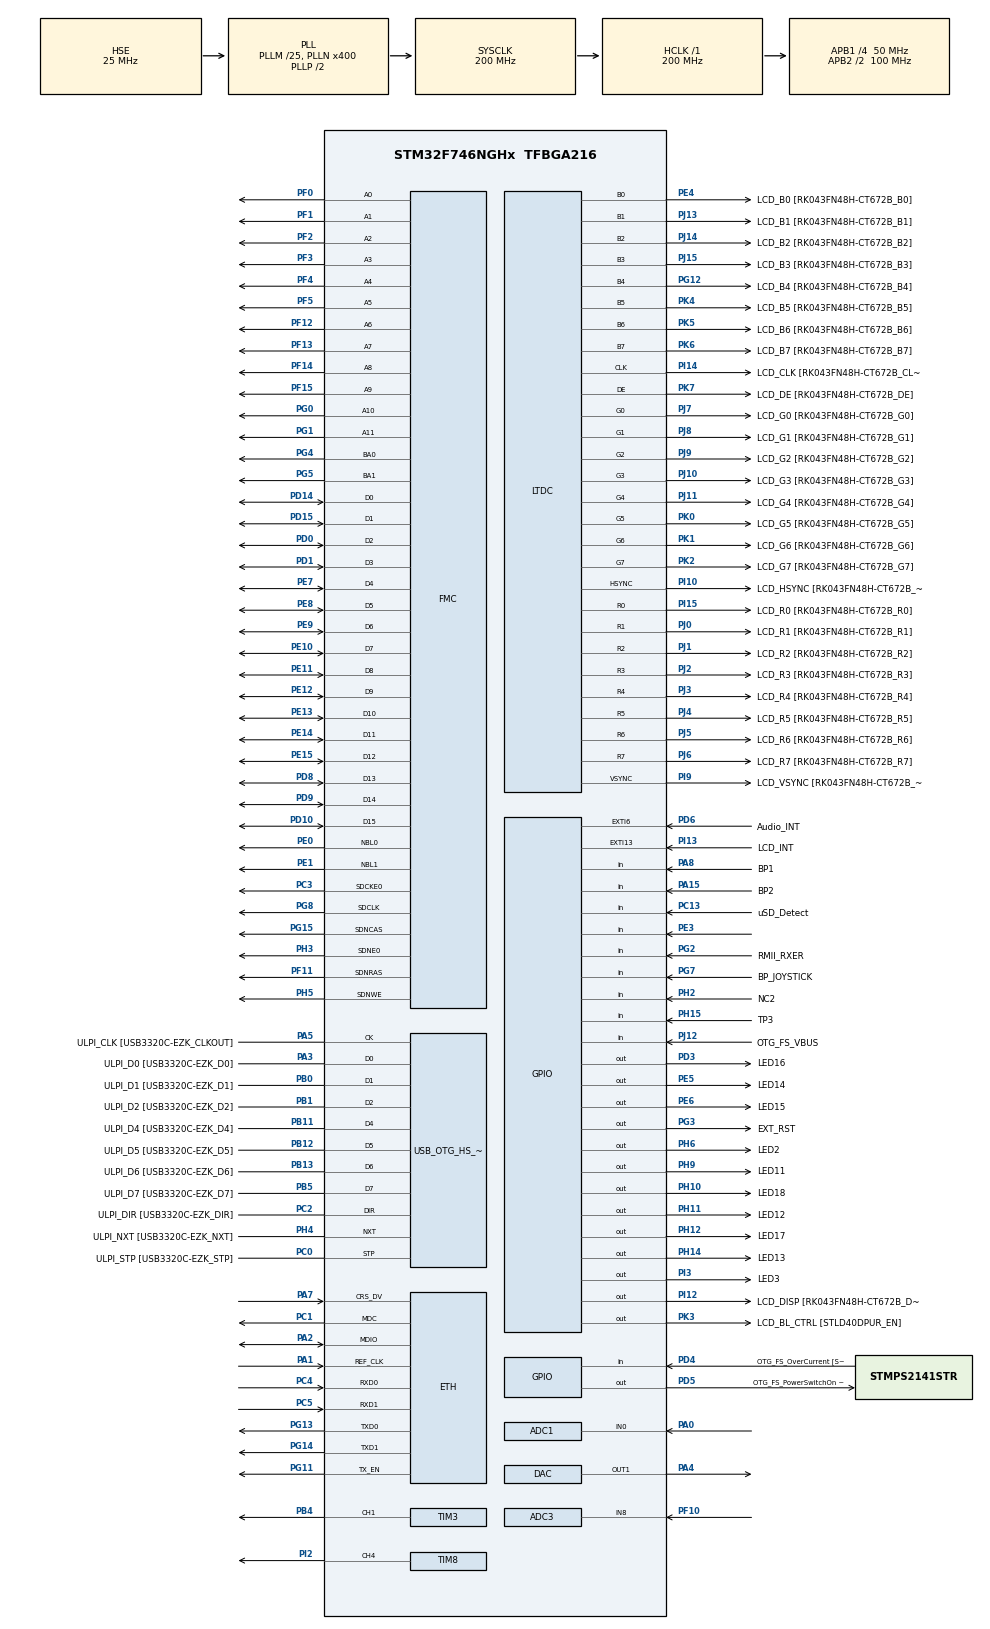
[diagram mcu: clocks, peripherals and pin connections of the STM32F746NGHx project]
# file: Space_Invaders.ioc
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ADC1.Channel-1\#ChannelRegularConversion=ADC_CHANNEL_0
ADC1.NbrOfConversionFlag=1
ADC1.Rank-1\#ChannelRegularConversion=1
ADC1.SamplingTime-1\#ChannelRegularConversion=ADC_SAMPLETIME_3CYCLES
ADC1.master=1
ADC3.Channel-0\#ChannelRegularConversion=ADC_CHANNEL_8
CORTEX_M7.PREFETCH_ENABLE=1
ETH.MACAddr=00\:80\:E1\:00\:E0\:00
ETH.MediaInterface=ETH_MEDIA_INTERFACE_RMII
FREERTOS.INCLUDE_vTaskDelayUntil=1
FREERTOS.Mutexes01=MutexLCD,Dynamic,NULL
FREERTOS.Queues01=Queue_F,8,enum End_type,0,Dynamic,NULL,NULL;Queue_N,8,struct Missile,0,Dynamic,NULL,NULL;Queue_J,8,uint8_t,0,Dynamic,NULL,NULL;Queue_E,8,struct Collision,0,Dynamic,NULL,NULL
FREERTOS.Tasks01=GameMaster,2,1024,f_GameMaster,Default,NULL,Dynamic,NULL,NULL;Joueur_1,1,1024,f_Joueur_1,Default,NULL,Dynamic,NULL,NULL;Block_Enemie,-2,1024,f_block_enemie,Default,NULL,Dynamic,NULL,NULL;Projectile,0,1024,f_projectile,Default,NULL,Dynamic,Dynamic,NULL;HUD,-1,1024,f_HUD,Default,NULL,Dynamic,NULL,NULL
FREERTOS.configCHECK_FOR_STACK_OVERFLOW=2
FREERTOS.configENABLE_FPU=1
FREERTOS.configGENERATE_RUN_TIME_STATS=0
FREERTOS.configRECORD_STACK_HIGH_ADDRESS=1
FREERTOS.configTOTAL_HEAP_SIZE=32768
FREERTOS.configUSE_APPLICATION_TASK_TAG=1
FREERTOS.configUSE_COUNTING_SEMAPHORES=1
FREERTOS.configUSE_IDLE_HOOK=1
FREERTOS.configUSE_MALLOC_FAILED_HOOK=1
FREERTOS.configUSE_RECURSIVE_MUTEXES=1
LTDC.ActiveH=272
LTDC.ActiveW=480
LTDC.Alpha_L0=255
LTDC.BlendingFactor1_L0=LTDC_BLENDING_FACTOR1_PAxCA
LTDC.BlendingFactor2_L0=LTDC_BLENDING_FACTOR2_PAxCA
LTDC.FBStartAdress_L0=0xC0000000
LTDC.HBP=13
LTDC.HFP=32
LTDC.HSync=41
LTDC.ImageHeight_L0=272
LTDC.ImageWidth_L0=480
LTDC.Layers=0
LTDC.PixelFormat_L0=LTDC_PIXEL_FORMAT_RGB565
LTDC.VSync=10
LTDC.WindowX1_L0=480
LTDC.WindowY1_L0=272
LWIP.Version=v2.1.2_Cube
Mcu.Family=STM32F7
Mcu.Name=STM32F746NGHx
Mcu.Package=TFBGA216
NVIC.ETH_IRQn=true\:5\:0\:false\:false\:true\:true\:false\:true
NVIC.LTDC_IRQn=true\:5\:0\:false\:false\:true\:true\:true\:true
NVIC.PriorityGroup=NVIC_PRIORITYGROUP_4
NVIC.TIM6_DAC_IRQn=true\:0\:0\:false\:false\:true\:false\:false\:true
NVIC.TimeBase=TIM6_DAC_IRQn
NVIC.TimeBaseIP=TIM6
PA0/WKUP.Signal=ADCx_IN0
PA1.Mode=RMII
PA1.Signal=ETH_REF_CLK
PA13.GPIO_Label=SWDIO
PA13.Mode=Serial_Wire
PA13.Signal=SYS_JTMS-SWDIO
PA14.GPIO_Label=SWCLK
PA14.Mode=Serial_Wire
PA14.Signal=SYS_JTCK-SWCLK
PA15.GPIO_Label=BP2
PA15.Signal=GPIO_Input
PA2.Mode=RMII
PA2.Signal=ETH_MDIO
PA3.GPIO_Label=ULPI_D0 [USB3320C-EZK_D0]
PA3.Mode=Host_HS
PA3.Signal=USB_OTG_HS_ULPI_D0
PA4.Signal=COMP_DAC1_group
PA5.GPIO_Label=ULPI_CLK [USB3320C-EZK_CLKOUT]
PA5.Mode=Host_HS
PA5.Signal=USB_OTG_HS_ULPI_CK
PA7.Mode=RMII
PA7.Signal=ETH_CRS_DV
PA8.GPIO_Label=BP1
PA8.Signal=GPIO_Input
PA9.GPIO_Label=VCP_TX [STM32F103CBT6_PA3]
PA9.GPIO_Mode=GPIO_MODE_AF_PP
PA9.GPIO_PuPd=GPIO_NOPULL
PA9.GPIO_Speed=GPIO_SPEED_FREQ_LOW
PA9.Signal=USART1_TX
PB0.GPIO_Label=ULPI_D1 [USB3320C-EZK_D1]
PB0.Mode=Host_HS
PB0.Signal=USB_OTG_HS_ULPI_D1
PB1.GPIO_Label=ULPI_D2 [USB3320C-EZK_D2]
PB1.Mode=Host_HS
PB1.Signal=USB_OTG_HS_ULPI_D2
PB11.GPIO_Label=ULPI_D4 [USB3320C-EZK_D4]
PB11.Mode=Host_HS
PB11.Signal=USB_OTG_HS_ULPI_D4
PB12.GPIO_Label=ULPI_D5 [USB3320C-EZK_D5]
PB12.Mode=Host_HS
PB12.Signal=USB_OTG_HS_ULPI_D5
PB13.GPIO_Label=ULPI_D6 [USB3320C-EZK_D6]
PB13.Mode=Host_HS
PB13.Signal=USB_OTG_HS_ULPI_D6
PB14.Signal=SPI2_MISO
PB15.Signal=SPI2_MOSI
PB4.Signal=S_TIM3_CH1
PB5.GPIO_Label=ULPI_D7 [USB3320C-EZK_D7]
PB5.Mode=Host_HS
PB5.Signal=USB_OTG_HS_ULPI_D7
PB7.GPIO_Label=VCP_RX [STM32F103CBT6_PA2]
PB7.GPIO_Mode=GPIO_MODE_AF_PP
PB7.GPIO_PuPd=GPIO_NOPULL
PB7.GPIO_Speed=GPIO_SPEED_FREQ_LOW
PB7.Signal=USART1_RX
PB8.GPIO_Label=ARDUINO SCL/D15
PB8.GPIO_Mode=GPIO_MODE_AF_OD
PB8.GPIO_PuPd=GPIO_NOPULL
PB8.GPIO_Speed=GPIO_SPEED_FREQ_LOW
PB8.Signal=I2C1_SCL
PB9.GPIO_Label=ARDUINO SDA/D14
PB9.GPIO_Mode=GPIO_MODE_AF_OD
PB9.GPIO_PuPd=GPIO_NOPULL
PB9.GPIO_Speed=GPIO_SPEED_FREQ_LOW
PB9.Signal=I2C1_SDA
PC0.GPIO_Label=ULPI_STP [USB3320C-EZK_STP]
PC0.Mode=Host_HS
PC0.Signal=USB_OTG_HS_ULPI_STP
PC1.Mode=RMII
PC1.Signal=ETH_MDC
PC13.GPIO_Label=uSD_Detect
PC13.Signal=GPIO_Input
PC14/OSC32_IN.GPIO_Label=RCC_OSC32_IN
PC14/OSC32_IN.Mode=LSE-External-Oscillator
PC14/OSC32_IN.Signal=RCC_OSC32_IN
PC15/OSC32_OUT.GPIO_Label=RCC_OSC32_OUT
PC15/OSC32_OUT.Mode=LSE-External-Oscillator
PC15/OSC32_OUT.Signal=RCC_OSC32_OUT
PC2.GPIO_Label=ULPI_DIR [USB3320C-EZK_DIR]
PC2.Mode=Host_HS
PC2.Signal=USB_OTG_HS_ULPI_DIR
PC3.Mode=SdramChipSelect1_1
PC3.Signal=FMC_SDCKE0
PC4.Mode=RMII
PC4.Signal=ETH_RXD0
PC5.Mode=RMII
PC5.Signal=ETH_RXD1
PC6.Signal=USART6_TX
PC7.Signal=USART6_RX
PD0.Signal=FMC_D2_DA2
PD1.Signal=FMC_D3_DA3
PD10.Signal=FMC_D15_DA15
PD14.Signal=FMC_D0_DA0
PD15.Signal=FMC_D1_DA1
PD3.GPIO_Label=LED16
PD3.Signal=GPIO_Output
PD4.GPIO_Label=OTG_FS_OverCurrent [STMPS2141STR_Fault]
PD4.Signal=GPIO_Input
PD5.GPIO_Label=OTG_FS_PowerSwitchOn [STMPS2141STR_EN]
PD5.PinState=GPIO_PIN_SET
PD5.Signal=GPIO_Output
PD6.GPIO_Label=Audio_INT
PD6.GPIO_ModeDefaultEXTI=GPIO_MODE_EVT_RISING
PD6.Signal=GPXTI6
PD8.Signal=FMC_D13_DA13
PD9.Signal=FMC_D14_DA14
PE0.Signal=FMC_NBL0
PE1.Signal=FMC_NBL1
PE10.Signal=FMC_D7_DA7
PE11.Signal=FMC_D8_DA8
PE12.Signal=FMC_D9_DA9
PE13.Signal=FMC_D10_DA10
PE14.Signal=FMC_D11_DA11
PE15.Signal=FMC_D12_DA12
PE3.Signal=GPIO_Input
PE4.GPIO_Label=LCD_B0 [RK043FN48H-CT672B_B0]
PE4.Mode=RGB888
PE4.Signal=LTDC_B0
PE5.GPIO_Label=LED14
PE5.Signal=GPIO_Output
PE6.GPIO_Label=LED15
PE6.Signal=GPIO_Output
PE7.Signal=FMC_D4_DA4
PE8.Signal=FMC_D5_DA5
PE9.Signal=FMC_D6_DA6
PF0.Signal=FMC_A0
PF1.Signal=FMC_A1
PF10.Mode=IN8
PF10.Signal=ADC3_IN8
PF11.Signal=FMC_SDNRAS
PF12.Signal=FMC_A6
PF13.Signal=FMC_A7
PF14.Signal=FMC_A8
PF15.Signal=FMC_A9
PF2.Signal=FMC_A2
PF3.Signal=FMC_A3
PF4.Signal=FMC_A4
PF5.Signal=FMC_A5
PF7.Signal=UART7_TX
PF8.Signal=ADC3_IN6
PF9.Signal=ADC3_IN7
PG0.Signal=FMC_A10
PG1.Signal=FMC_A11
PG11.Mode=RMII
PG11.Signal=ETH_TX_EN
PG12.GPIO_Label=LCD_B4 [RK043FN48H-CT672B_B4]
PG12.Mode=RGB888
PG12.Signal=LTDC_B4
PG13.Mode=RMII
PG13.Signal=ETH_TXD0
PG14.Mode=RMII
PG14.Signal=ETH_TXD1
PG15.Signal=FMC_SDNCAS
PG2.GPIO_Label=RMII_RXER
PG2.Signal=GPIO_Input
PG3.GPIO_Label=EXT_RST
PG3.Signal=GPIO_Output
PG4.Signal=FMC_A14_BA0
PG5.Signal=FMC_A15_BA1
PG7.GPIO_Label=BP_JOYSTICK
PG7.Signal=GPIO_Input
PG8.Signal=FMC_SDCLK
PH0/OSC_IN.GPIO_Label=OSC_25M [NZ2520SB-25.00M_OUT]
PH0/OSC_IN.Mode=HSE-External-Oscillator
PH0/OSC_IN.Signal=RCC_OSC_IN
PH1/OSC_OUT.Mode=HSE-External-Oscillator
PH1/OSC_OUT.Signal=RCC_OSC_OUT
PH10.GPIO_Label=LED18
PH10.Signal=GPIO_Output
PH11.GPIO_Label=LED12
PH11.Signal=GPIO_Output
PH12.GPIO_Label=LED17
PH12.Signal=GPIO_Output
PH14.GPIO_Label=LED13
PH14.Signal=GPIO_Output
PH15.GPIO_Label=TP3
PH15.Signal=GPIO_Input
PH2.GPIO_Label=NC2
PH2.Signal=GPIO_Input
PH3.Mode=SdramChipSelect1_1
PH3.Signal=FMC_SDNE0
PH4.GPIO_Label=ULPI_NXT [USB3320C-EZK_NXT]
PH4.Mode=Host_HS
PH4.Signal=USB_OTG_HS_ULPI_NXT
PH5.Signal=FMC_SDNWE
PH6.GPIO_Label=LED2
PH6.Signal=GPIO_Output
PH7.GPIO_Label=LCD_SCL [RK043FN48H-CT672B_SCL]
PH7.Signal=I2C3_SCL
PH8.GPIO_Label=LCD_SDA [RK043FN48H-CT672B_SDA]
PH8.Signal=I2C3_SDA
PH9.GPIO_Label=LED11
PH9.Signal=GPIO_Output
PI0.Signal=SPI2_NSS
PI1.GPIO_Label=ARDUINO SCK/D13
PI1.GPIO_Mode=GPIO_MODE_AF_PP
PI1.GPIO_PuPd=GPIO_NOPULL
PI1.GPIO_Speed=GPIO_SPEED_FREQ_LOW
PI1.Signal=SPI2_SCK
PI10.GPIO_Label=LCD_HSYNC [RK043FN48H-CT672B_HSYNC]
PI10.Mode=RGB888
PI10.Signal=LTDC_HSYNC
PI12.GPIO_Label=LCD_DISP [RK043FN48H-CT672B_DISP] 
PI12.PinState=GPIO_PIN_SET
PI12.Signal=GPIO_Output
PI13.GPIO_Label=LCD_INT
PI13.GPIO_ModeDefaultEXTI=GPIO_MODE_EVT_RISING
PI13.Signal=GPXTI13
PI14.GPIO_Label=LCD_CLK [RK043FN48H-CT672B_CLK]
PI14.Mode=RGB888
PI14.Signal=LTDC_CLK
PI15.GPIO_Label=LCD_R0 [RK043FN48H-CT672B_R0]
PI15.Mode=RGB888
PI15.Signal=LTDC_R0
PI2.Signal=S_TIM8_CH4
PI3.GPIO_Label=LED3
PI3.Signal=GPIO_Output
PI8.GPIO_Label=NC1 [TP2]
PI8.Signal=RTC_TS
PI9.GPIO_Label=LCD_VSYNC [RK043FN48H-CT672B_VSYNC]
PI9.Mode=RGB888
PI9.Signal=LTDC_VSYNC
PJ0.GPIO_Label=LCD_R1 [RK043FN48H-CT672B_R1]
PJ0.Mode=RGB888
PJ0.Signal=LTDC_R1
PJ1.GPIO_Label=LCD_R2 [RK043FN48H-CT672B_R2]
PJ1.Mode=RGB888
PJ1.Signal=LTDC_R2
PJ10.GPIO_Label=LCD_G3 [RK043FN48H-CT672B_G3]
PJ10.Mode=RGB888
PJ10.Signal=LTDC_G3
PJ11.GPIO_Label=LCD_G4 [RK043FN48H-CT672B_G4]
PJ11.Mode=RGB888
PJ11.Signal=LTDC_G4
PJ12.GPIO_Label=OTG_FS_VBUS
PJ12.Signal=GPIO_Input
PJ13.GPIO_Label=LCD_B1 [RK043FN48H-CT672B_B1]
PJ13.Mode=RGB888
PJ13.Signal=LTDC_B1
PJ14.GPIO_Label=LCD_B2 [RK043FN48H-CT672B_B2]
PJ14.Mode=RGB888
PJ14.Signal=LTDC_B2
PJ15.GPIO_Label=LCD_B3 [RK043FN48H-CT672B_B3]
PJ15.Mode=RGB888
PJ15.Signal=LTDC_B3
PJ2.GPIO_Label=LCD_R3 [RK043FN48H-CT672B_R3]
PJ2.Mode=RGB888
PJ2.Signal=LTDC_R3
PJ3.GPIO_Label=LCD_R4 [RK043FN48H-CT672B_R4]
PJ3.Mode=RGB888
PJ3.Signal=LTDC_R4
PJ4.GPIO_Label=LCD_R5 [RK043FN48H-CT672B_R5]
PJ4.Mode=RGB888
PJ4.Signal=LTDC_R5
PJ5.GPIO_Label=LCD_R6 [RK043FN48H-CT672B_R6]
PJ5.Mode=RGB888
PJ5.Signal=LTDC_R6
PJ6.GPIO_Label=LCD_R7 [RK043FN48H-CT672B_R7]
PJ6.Mode=RGB888
PJ6.Signal=LTDC_R7
PJ7.GPIO_Label=LCD_G0 [RK043FN48H-CT672B_G0]
PJ7.Mode=RGB888
PJ7.Signal=LTDC_G0
PJ8.GPIO_Label=LCD_G1 [RK043FN48H-CT672B_G1]
PJ8.Mode=RGB888
PJ8.Signal=LTDC_G1
PJ9.GPIO_Label=LCD_G2 [RK043FN48H-CT672B_G2]
PJ9.Mode=RGB888
PJ9.Signal=LTDC_G2
PK0.GPIO_Label=LCD_G5 [RK043FN48H-CT672B_G5]
PK0.Mode=RGB888
PK0.Signal=LTDC_G5
PK1.GPIO_Label=LCD_G6 [RK043FN48H-CT672B_G6]
PK1.Mode=RGB888
PK1.Signal=LTDC_G6
PK2.GPIO_Label=LCD_G7 [RK043FN48H-CT672B_G7]
PK2.Mode=RGB888
PK2.Signal=LTDC_G7
PK3.GPIO_Label=LCD_BL_CTRL [STLD40DPUR_EN]
PK3.GPIO_Speed=GPIO_SPEED_FREQ_LOW
PK3.PinState=GPIO_PIN_SET
PK3.Signal=GPIO_Output
PK4.GPIO_Label=LCD_B5 [RK043FN48H-CT672B_B5]
PK4.Mode=RGB888
PK4.Signal=LTDC_B5
PK5.GPIO_Label=LCD_B6 [RK043FN48H-CT672B_B6]
PK5.Mode=RGB888
PK5.Signal=LTDC_B6
PK6.GPIO_Label=LCD_B7 [RK043FN48H-CT672B_B7]
PK6.Mode=RGB888
PK6.Signal=LTDC_B7
PK7.GPIO_Label=LCD_DE [RK043FN48H-CT672B_DE]
PK7.Mode=RGB888
PK7.Signal=LTDC_DE
ProjectManager.HeapSize=0x200
ProjectManager.StackSize=0x400
ProjectManager.TargetToolchain=STM32CubeIDE
RCC.AHBFreq_Value=200000000
RCC.APB1CLKDivider=RCC_HCLK_DIV4
RCC.APB1Freq_Value=50000000
RCC.APB1TimFreq_Value=100000000
RCC.APB2CLKDivider=RCC_HCLK_DIV2
RCC.APB2Freq_Value=100000000
RCC.APB2TimFreq_Value=200000000
RCC.CortexFreq_Value=200000000
RCC.HCLKFreq_Value=200000000
RCC.HSE_VALUE=25000000
RCC.HSI_VALUE=16000000
RCC.PLL48CLockSelection=RCC_CLK48SOURCE_PLLSAIP
RCC.PLLI2SN=100
RCC.PLLM=25
RCC.PLLN=400
RCC.PLLQ=9
RCC.PLLSAIN=384
RCC.PLLSAIP=RCC_PLLSAIP_DIV8
RCC.PLLSAIR=5
RCC.PLLSAIRDiv=RCC_PLLSAIDIVR_8
RCC.PLLSourceVirtual=RCC_PLLSOURCE_HSE
RCC.SDMMCClockSelection=RCC_SDMMC1CLKSOURCE_CLK48
RCC.SYSCLKFreq_VALUE=200000000
RCC.SYSCLKSource=RCC_SYSCLKSOURCE_PLLCLK
RCC.USBFreq_Value=48000000
RCC.VCOOutputFreq_Value=400000000
SH.ADCx_IN0.0=ADC1_IN0,IN0
SH.COMP_DAC1_group.0=DAC_OUT1,DAC_OUT1
SH.FMC_A0.0=FMC_A0,12b-sda1
SH.FMC_A1.0=FMC_A1,12b-sda1
SH.FMC_A10.0=FMC_A10,12b-sda1
SH.FMC_A11.0=FMC_A11,12b-sda1
SH.FMC_A14_BA0.0=FMC_BA0,FourSdramBanks1
SH.FMC_A15_BA1.0=FMC_BA1,FourSdramBanks1
SH.FMC_A2.0=FMC_A2,12b-sda1
SH.FMC_A3.0=FMC_A3,12b-sda1
SH.FMC_A4.0=FMC_A4,12b-sda1
SH.FMC_A5.0=FMC_A5,12b-sda1
SH.FMC_A6.0=FMC_A6,12b-sda1
SH.FMC_A7.0=FMC_A7,12b-sda1
SH.FMC_A8.0=FMC_A8,12b-sda1
SH.FMC_A9.0=FMC_A9,12b-sda1
SH.FMC_D0_DA0.0=FMC_D0,sd-16b-d1
SH.FMC_D10_DA10.0=FMC_D10,sd-16b-d1
SH.FMC_D11_DA11.0=FMC_D11,sd-16b-d1
SH.FMC_D12_DA12.0=FMC_D12,sd-16b-d1
SH.FMC_D13_DA13.0=FMC_D13,sd-16b-d1
SH.FMC_D14_DA14.0=FMC_D14,sd-16b-d1
SH.FMC_D15_DA15.0=FMC_D15,sd-16b-d1
SH.FMC_D1_DA1.0=FMC_D1,sd-16b-d1
SH.FMC_D2_DA2.0=FMC_D2,sd-16b-d1
SH.FMC_D3_DA3.0=FMC_D3,sd-16b-d1
SH.FMC_D4_DA4.0=FMC_D4,sd-16b-d1
SH.FMC_D5_DA5.0=FMC_D5,sd-16b-d1
SH.FMC_D6_DA6.0=FMC_D6,sd-16b-d1
SH.FMC_D7_DA7.0=FMC_D7,sd-16b-d1
SH.FMC_D8_DA8.0=FMC_D8,sd-16b-d1
SH.FMC_D9_DA9.0=FMC_D9,sd-16b-d1
SH.FMC_NBL0.0=FMC_NBL0,Sd2ByteEnable1
SH.FMC_NBL1.0=FMC_NBL1,Sd2ByteEnable1
SH.FMC_SDCLK.0=FMC_SDCLK,12b-sda1
SH.FMC_SDNCAS.0=FMC_SDNCAS,12b-sda1
SH.FMC_SDNRAS.0=FMC_SDNRAS,12b-sda1
SH.FMC_SDNWE.0=FMC_SDNWE,12b-sda1
SH.S_TIM3_CH1.0=TIM3_CH1,PWM Generation1 CH1
SH.S_TIM8_CH4.0=TIM8_CH4,PWM Generation4 CH4
TIM3.Channel-PWM\ Generation1\ CH1=TIM_CHANNEL_1
TIM8.Channel-PWM\ Generation4\ CH4=TIM_CHANNEL_4
VP_CRC_VS_CRC.Mode=CRC_Activate
VP_DMA2D_VS_DMA2D.Mode=DMA2D_Activate
VP_FREERTOS_VS_CMSIS_V1.Mode=CMSIS_V1
VP_LWIP_VS_Enabled.Mode=Enabled
VP_RNG_VS_RNG.Mode=RNG_Activate
VP_SYS_VS_tim6.Mode=TIM6
VP_TIM1_VS_ClockSourceINT.Mode=Internal
VP_TIM2_VS_ClockSourceINT.Mode=Internal
VP_TIM3_VS_ClockSourceINT.Mode=Internal
VP_TIM3_VS_ClockSourceITR.Mode=TriggerSource_ITR0
VP_TIM5_VS_ClockSourceINT.Mode=Internal
VP_TIM8_VS_ClockSourceINT.Mode=Internal
board=STM32F746G-DISCO

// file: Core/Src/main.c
/* USER CODE BEGIN Header */
/**
 ******************************************************************************
 * @file           : main.c
 * @brief          : Main program body
 ******************************************************************************
 * @attention
 *
 * <h2><center>&copy; Copyright (c) 2021 STMicroelectronics.
 * All rights reserved.</center></h2>
 *
 * This software component is licensed by ST under Ultimate Liberty license
 * SLA0044, the "License"; You may not use this file except in compliance with
 * the License. You may obtain a copy of the License at:
 *                             www.st.com/SLA0044
 *
 *
 *                             Bonjour ! J'aime beaucoup l'informatique industrielle
 *
 *                             Licorne magique
 *
 ******************************************************************************
 */
/* USER CODE END Header */
#include "main.h"
#include "cmsis_os.h"
#include "lwip.h"

/* USER CODE BEGIN Includes */
#include "stm32746g_discovery_lcd.h"
#include "stm32746g_discovery_ts.h"
#include "stdio.h"
#include "semphr.h"
/* USER CODE END Includes */

/* USER CODE BEGIN PD */
#define FACTEUR_ECRAN 1;
/* USER CODE END PD */

ADC_HandleTypeDef hadc1;
ADC_HandleTypeDef hadc3;

CRC_HandleTypeDef hcrc;

DAC_HandleTypeDef hdac;

DMA2D_HandleTypeDef hdma2d;

LTDC_HandleTypeDef hltdc;

RNG_HandleTypeDef hrng;

TIM_HandleTypeDef htim1;
TIM_HandleTypeDef htim2;
TIM_HandleTypeDef htim3;
TIM_HandleTypeDef htim5;
TIM_HandleTypeDef htim8;

SDRAM_HandleTypeDef hsdram1;

osThreadId GameMasterHandle;
osThreadId Joueur_1Handle;
osThreadId Block_EnemieHandle;
osThreadId ProjectileHandle;
osThreadId HUDHandle;
osMessageQId Queue_FHandle;
osMessageQId Queue_NHandle;
osMessageQId Queue_JHandle;
osMessageQId Queue_EHandle;
osMutexId MutexLCDHandle;

void SystemClock_Config(void);
static void MX_GPIO_Init(void);
static void MX_ADC3_Init(void);
static void MX_LTDC_Init(void);
static void MX_TIM1_Init(void);
static void MX_TIM2_Init(void);
static void MX_TIM3_Init(void);
static void MX_TIM5_Init(void);
static void MX_TIM8_Init(void);
static void MX_DAC_Init(void);
static void MX_FMC_Init(void);
static void MX_DMA2D_Init(void);
static void MX_CRC_Init(void);
static void MX_RNG_Init(void);
static void MX_ADC1_Init(void);
void f_GameMaster(void const *argument);
void f_Joueur_1(void const *argument);
void f_block_enemie(void const *argument);
void f_projectile(void const *argument);
void f_HUD(void const *argument);

/* USER CODE BEGIN PFP */
uint8_t proba_bernoulli(uint32_t numerateur, uint32_t denominateur);
/* USER CODE END PFP */

/* USER CODE BEGIN 0 */

enum Camps_missile
{
  MISSILE_AMI,
  MISSILE_ENNEMI
};

enum End_type
{
  END_TABLEAU_VIDE,
  END_MORT_JOUEUR
};

enum Sens_ennemie
{
  DROITE,
  GAUCHE
};

const uint16_t joueur_width = 20;
const uint16_t joueur_height = 20;

const uint16_t monstre_width = 25;
const uint16_t monstre_height = 15;

struct Missile
{
  int16_t x;
  int16_t y;
  int8_t dx;
  int8_t dy;
  enum Camps_missile equipe;
  uint8_t damage;
  uint8_t valide;
};

struct Joueur
{
  // uint32_t et pas 16 car fonction d'affichage bitmap (j'en sais pas plus)
  int32_t x;              // Position de l'angle superieur gauche
  int32_t y;              // Position de l'angle superieur gauche
  int8_t dx;              // Vitesse du joueur
  int8_t dy;              // Vitesse du joueur
  int8_t health;          // Vie du joueur
  struct Missile missile; // Missile lancé par le joueur
};

struct Monster
{
  int32_t x;
  int32_t y;
  int16_t health;
  // uint8_t pbmp; // TODO c'est quoi ca ?
  // uint8_t type; // TODO d'autre ennemies ?
  struct Missile missile;
};

struct Collision
{
  uint8_t idx1;
  uint8_t idx2;
  uint8_t damage;
};

// Définition des paramètres du joueurs

struct Joueur joueur = {200, 200, 1, 1, 3, {0, 0, 0, -1, MISSILE_AMI, 1, 1}};

uint8_t LED = 1;

uint32_t LCD_COLOR_BACKGROUND = LCD_COLOR_BLACK;

// Number of waves of enemies before the game is won.
uint8_t wave = 0;

// Tableau des monstres (8 par ligne, sur 3 ligne)
struct Monster Table_ennemis[8][3];

/* USER CODE END 0 */

int main(void)
{
  /* USER CODE BEGIN 1 */
  static TS_StateTypeDef TS_State;
  ADC_ChannelConfTypeDef sConfig = {0};
  sConfig.Rank = ADC_REGULAR_RANK_1;
  sConfig.SamplingTime = ADC_SAMPLETIME_3CYCLES;

  /* USER CODE END 1 */

  /* MCU Configuration--------------------------------------------------------*/

  /* Reset of all peripherals, Initializes the Flash interface and the Systick. */
  HAL_Init();

  /* Configure the system clock */
  SystemClock_Config();

  /* Initialize all configured peripherals */
  MX_GPIO_Init();
  MX_ADC3_Init();
  MX_LTDC_Init();
  MX_TIM1_Init();
  MX_TIM2_Init();
  MX_TIM3_Init();
  MX_TIM5_Init();
  MX_TIM8_Init();
  MX_DAC_Init();
  MX_FMC_Init();
  MX_DMA2D_Init();
  MX_CRC_Init();
  MX_RNG_Init();
  MX_ADC1_Init();
  /* USER CODE BEGIN 2 */
  BSP_LCD_Init();
  BSP_LCD_LayerDefaultInit(0, LCD_FB_START_ADDRESS);
  BSP_LCD_LayerDefaultInit(1,
                           LCD_FB_START_ADDRESS + BSP_LCD_GetXSize() * BSP_LCD_GetYSize() * 4);
  BSP_LCD_DisplayOn();
  BSP_LCD_SelectLayer(1);
  BSP_LCD_Clear(LCD_COLOR_BLACK);
  BSP_LCD_SetFont(&Font12);
  BSP_LCD_SetTextColor(LCD_COLOR_BLUE);
  BSP_LCD_SetBackColor(LCD_COLOR_BLACK);

  BSP_TS_Init(BSP_LCD_GetXSize(), BSP_LCD_GetYSize());

  /* USER CODE END 2 */

  /* Create the mutex(es) */
  /* definition and creation of MutexLCD */
  osMutexDef(MutexLCD);
  MutexLCDHandle = osMutexCreate(osMutex(MutexLCD));

  /* Create the queue(s) */
  /* definition and creation of Queue_F */
  osMessageQDef(Queue_F, 8, enum End_type);
  Queue_FHandle = osMessageCreate(osMessageQ(Queue_F), NULL);

  /* definition and creation of Queue_N */
  osMessageQDef(Queue_N, 8, struct Missile);
  Queue_NHandle = osMessageCreate(osMessageQ(Queue_N), NULL);

  /* definition and creation of Queue_J */
  osMessageQDef(Queue_J, 8, uint8_t);
  Queue_JHandle = osMessageCreate(osMessageQ(Queue_J), NULL);

  /* definition and creation of Queue_E */
  osMessageQDef(Queue_E, 8, struct Collision);
  Queue_EHandle = osMessageCreate(osMessageQ(Queue_E), NULL);

  /* Create the thread(s) */
  /* definition and creation of GameMaster */
  osThreadDef(GameMaster, f_GameMaster, osPriorityHigh, 0, 1024);
  GameMasterHandle = osThreadCreate(osThread(GameMaster), NULL);

  /* definition and creation of Joueur_1 */
  osThreadDef(Joueur_1, f_Joueur_1, osPriorityAboveNormal, 0, 1024);
  Joueur_1Handle = osThreadCreate(osThread(Joueur_1), NULL);

  /* definition and creation of Block_Enemie */
  osThreadDef(Block_Enemie, f_block_enemie, osPriorityLow, 0, 1024);
  Block_EnemieHandle = osThreadCreate(osThread(Block_Enemie), NULL);

  /* definition and creation of Projectile */
  osThreadDef(Projectile, f_projectile, osPriorityNormal, 0, 1024);
  ProjectileHandle = osThreadCreate(osThread(Projectile), NULL);

  /* definition and creation of HUD */
  osThreadDef(HUD, f_HUD, osPriorityBelowNormal, 0, 1024);
  HUDHandle = osThreadCreate(osThread(HUD), NULL);

  /* USER CODE BEGIN RTOS_THREADS */
  vQueueAddToRegistry(Queue_NHandle, "Queue Missile");
  vQueueAddToRegistry(Queue_JHandle, "Queue Missile");
  vQueueAddToRegistry(Queue_EHandle, "Queue Missile");
  vQueueAddToRegistry(Queue_FHandle, "Queue Missile");
  /* USER CODE END RTOS_THREADS */

  /* Start scheduler */
  osKernelStart();

  /* We should never get here as control is now taken by the scheduler */
  /* Infinite loop */
  /* USER CODE BEGIN WHILE */
  while (1)
  {
    /* Code de base */
    //    HAL_GPIO_WritePin(LED13_GPIO_Port, LED13_Pin,
    //                      HAL_GPIO_ReadPin(BP1_GPIO_Port, BP1_Pin));
    //    HAL_GPIO_WritePin(LED14_GPIO_Port, LED14_Pin,
    //                      HAL_GPIO_ReadPin(BP2_GPIO_Port, BP2_Pin));
    //    sprintf(text, "BP1 : %d", HAL_GPIO_ReadPin(BP1_GPIO_Port, BP1_Pin));
    //    BSP_LCD_DisplayStringAtLine(5, (uint8_t *)text);

    ;

    sConfig.Channel = ADC_CHANNEL_7;
    HAL_ADC_ConfigChannel(&hadc3, &sConfig);
    HAL_ADC_Start(&hadc3);

    sConfig.Channel = ADC_CHANNEL_6;
    HAL_ADC_ConfigChannel(&hadc3, &sConfig);
    HAL_ADC_Start(&hadc3);
    sConfig.Channel = ADC_CHANNEL_8;
    HAL_ADC_ConfigChannel(&hadc3, &sConfig);
    HAL_ADC_Start(&hadc3);

    HAL_ADC_Start(&hadc1);

    BSP_TS_GetState(&TS_State);
    if (TS_State.touchDetected)
    {
      BSP_LCD_FillCircle(TS_State.touchX[0], TS_State.touchY[0], 4);
    }
    /* USER CODE END WHILE */

  }
}

void SystemClock_Config(void)
{
  RCC_OscInitTypeDef RCC_OscInitStruct = {0};
  RCC_ClkInitTypeDef RCC_ClkInitStruct = {0};
  RCC_PeriphCLKInitTypeDef PeriphClkInitStruct = {0};

  /** Configure LSE Drive Capability
  */
  HAL_PWR_EnableBkUpAccess();
  /** Configure the main internal regulator output voltage
  */
  __HAL_RCC_PWR_CLK_ENABLE();
  __HAL_PWR_VOLTAGESCALING_CONFIG(PWR_REGULATOR_VOLTAGE_SCALE1);
  /** Initializes the RCC Oscillators according to the specified parameters
  * in the RCC_OscInitTypeDef structure.
  */
  RCC_OscInitStruct.OscillatorType = RCC_OSCILLATORTYPE_HSE;
  RCC_OscInitStruct.HSEState = RCC_HSE_ON;
  RCC_OscInitStruct.PLL.PLLState = RCC_PLL_ON;
  RCC_OscInitStruct.PLL.PLLSource = RCC_PLLSOURCE_HSE;
  RCC_OscInitStruct.PLL.PLLM = 25;
  RCC_OscInitStruct.PLL.PLLN = 400;
  RCC_OscInitStruct.PLL.PLLP = RCC_PLLP_DIV2;
  RCC_OscInitStruct.PLL.PLLQ = 9;
  if (HAL_RCC_OscConfig(&RCC_OscInitStruct) != HAL_OK)
  {
    Error_Handler();
  }
  /** Activate the Over-Drive mode
  */
  if (HAL_PWREx_EnableOverDrive() != HAL_OK)
  {
    Error_Handler();
  }
  /** Initializes the CPU, AHB and APB buses clocks
  */
  RCC_ClkInitStruct.ClockType = RCC_CLOCKTYPE_HCLK | RCC_CLOCKTYPE_SYSCLK | RCC_CLOCKTYPE_PCLK1 | RCC_CLOCKTYPE_PCLK2;
  RCC_ClkInitStruct.SYSCLKSource = RCC_SYSCLKSOURCE_PLLCLK;
  RCC_ClkInitStruct.AHBCLKDivider = RCC_SYSCLK_DIV1;
  RCC_ClkInitStruct.APB1CLKDivider = RCC_HCLK_DIV4;
  RCC_ClkInitStruct.APB2CLKDivider = RCC_HCLK_DIV2;

  if (HAL_RCC_ClockConfig(&RCC_ClkInitStruct, FLASH_LATENCY_6) != HAL_OK)
  {
    Error_Handler();
  }
  PeriphClkInitStruct.PeriphClockSelection = RCC_PERIPHCLK_LTDC | RCC_PERIPHCLK_CLK48;
  PeriphClkInitStruct.PLLSAI.PLLSAIN = 384;
  PeriphClkInitStruct.PLLSAI.PLLSAIR = 5;
  PeriphClkInitStruct.PLLSAI.PLLSAIQ = 2;
  PeriphClkInitStruct.PLLSAI.PLLSAIP = RCC_PLLSAIP_DIV8;
  PeriphClkInitStruct.PLLSAIDivQ = 1;
  PeriphClkInitStruct.PLLSAIDivR = RCC_PLLSAIDIVR_8;
  PeriphClkInitStruct.Clk48ClockSelection = RCC_CLK48SOURCE_PLLSAIP;
  if (HAL_RCCEx_PeriphCLKConfig(&PeriphClkInitStruct) != HAL_OK)
  {
    Error_Handler();
  }
}

static void MX_ADC1_Init(void)
{

  ADC_ChannelConfTypeDef sConfig = {0};

  /** Configure the global features of the ADC (Clock, Resolution, Data Alignment and number of conversion)
  */
  hadc1.Instance = ADC1;
  hadc1.Init.ClockPrescaler = ADC_CLOCK_SYNC_PCLK_DIV4;
  hadc1.Init.Resolution = ADC_RESOLUTION_12B;
  hadc1.Init.ScanConvMode = ADC_SCAN_DISABLE;
  hadc1.Init.ContinuousConvMode = DISABLE;
  hadc1.Init.DiscontinuousConvMode = DISABLE;
  hadc1.Init.ExternalTrigConvEdge = ADC_EXTERNALTRIGCONVEDGE_NONE;
  hadc1.Init.ExternalTrigConv = ADC_SOFTWARE_START;
  hadc1.Init.DataAlign = ADC_DATAALIGN_RIGHT;
  hadc1.Init.NbrOfConversion = 1;
  hadc1.Init.DMAContinuousRequests = DISABLE;
  hadc1.Init.EOCSelection = ADC_EOC_SINGLE_CONV;
  if (HAL_ADC_Init(&hadc1) != HAL_OK)
  {
    Error_Handler();
  }
  /** Configure for the selected ADC regular channel its corresponding rank in the sequencer and its sample time.
  */
  sConfig.Channel = ADC_CHANNEL_0;
  sConfig.Rank = ADC_REGULAR_RANK_1;
  sConfig.SamplingTime = ADC_SAMPLETIME_3CYCLES;
  if (HAL_ADC_ConfigChannel(&hadc1, &sConfig) != HAL_OK)
  {
    Error_Handler();
  }
}

static void MX_ADC3_Init(void)
{

  ADC_ChannelConfTypeDef sConfig = {0};

  /** Configure the global features of the ADC (Clock, Resolution, Data Alignment and number of conversion)
  */
  hadc3.Instance = ADC3;
  hadc3.Init.ClockPrescaler = ADC_CLOCK_SYNC_PCLK_DIV4;
  hadc3.Init.Resolution = ADC_RESOLUTION_12B;
  hadc3.Init.ScanConvMode = ADC_SCAN_DISABLE;
  hadc3.Init.ContinuousConvMode = DISABLE;
  hadc3.Init.DiscontinuousConvMode = DISABLE;
  hadc3.Init.ExternalTrigConvEdge = ADC_EXTERNALTRIGCONVEDGE_NONE;
  hadc3.Init.ExternalTrigConv = ADC_SOFTWARE_START;
  hadc3.Init.DataAlign = ADC_DATAALIGN_RIGHT;
  hadc3.Init.NbrOfConversion = 1;
  hadc3.Init.DMAContinuousRequests = DISABLE;
  hadc3.Init.EOCSelection = ADC_EOC_SINGLE_CONV;
  if (HAL_ADC_Init(&hadc3) != HAL_OK)
  {
    Error_Handler();
  }
  /** Configure for the selected ADC regular channel its corresponding rank in the sequencer and its sample time.
  */
  sConfig.Channel = ADC_CHANNEL_8;
  sConfig.Rank = ADC_REGULAR_RANK_1;
  sConfig.SamplingTime = ADC_SAMPLETIME_3CYCLES;
  if (HAL_ADC_ConfigChannel(&hadc3, &sConfig) != HAL_OK)
  {
    Error_Handler();
  }
}

static void MX_CRC_Init(void)
{

  hcrc.Instance = CRC;
  hcrc.Init.DefaultPolynomialUse = DEFAULT_POLYNOMIAL_ENABLE;
  hcrc.Init.DefaultInitValueUse = DEFAULT_INIT_VALUE_ENABLE;
  hcrc.Init.InputDataInversionMode = CRC_INPUTDATA_INVERSION_NONE;
  hcrc.Init.OutputDataInversionMode = CRC_OUTPUTDATA_INVERSION_DISABLE;
  hcrc.InputDataFormat = CRC_INPUTDATA_FORMAT_BYTES;
  if (HAL_CRC_Init(&hcrc) != HAL_OK)
  {
    Error_Handler();
  }
}

static void MX_DAC_Init(void)
{

  DAC_ChannelConfTypeDef sConfig = {0};

  /** DAC Initialization
  */
  hdac.Instance = DAC;
  if (HAL_DAC_Init(&hdac) != HAL_OK)
  {
    Error_Handler();
  }
  /** DAC channel OUT1 config
  */
  sConfig.DAC_Trigger = DAC_TRIGGER_NONE;
  sConfig.DAC_OutputBuffer = DAC_OUTPUTBUFFER_ENABLE;
  if (HAL_DAC_ConfigChannel(&hdac, &sConfig, DAC_CHANNEL_1) != HAL_OK)
  {
    Error_Handler();
  }
}

static void MX_DMA2D_Init(void)
{

  hdma2d.Instance = DMA2D;
  hdma2d.Init.Mode = DMA2D_M2M;
  hdma2d.Init.ColorMode = DMA2D_OUTPUT_ARGB8888;
  hdma2d.Init.OutputOffset = 0;
  hdma2d.LayerCfg[1].InputOffset = 0;
  hdma2d.LayerCfg[1].InputColorMode = DMA2D_INPUT_ARGB8888;
  hdma2d.LayerCfg[1].AlphaMode = DMA2D_NO_MODIF_ALPHA;
  hdma2d.LayerCfg[1].InputAlpha = 0;
  if (HAL_DMA2D_Init(&hdma2d) != HAL_OK)
  {
    Error_Handler();
  }
  if (HAL_DMA2D_ConfigLayer(&hdma2d, 1) != HAL_OK)
  {
    Error_Handler();
  }
}

static void MX_LTDC_Init(void)
{

  LTDC_LayerCfgTypeDef pLayerCfg = {0};

  hltdc.Instance = LTDC;
  hltdc.Init.HSPolarity = LTDC_HSPOLARITY_AL;
  hltdc.Init.VSPolarity = LTDC_VSPOLARITY_AL;
  hltdc.Init.DEPolarity = LTDC_DEPOLARITY_AL;
  hltdc.Init.PCPolarity = LTDC_PCPOLARITY_IPC;
  hltdc.Init.HorizontalSync = 40;
  hltdc.Init.VerticalSync = 9;
  hltdc.Init.AccumulatedHBP = 53;
  hltdc.Init.AccumulatedVBP = 11;
  hltdc.Init.AccumulatedActiveW = 533;
  hltdc.Init.AccumulatedActiveH = 283;
  hltdc.Init.TotalWidth = 565;
  hltdc.Init.TotalHeigh = 285;
  hltdc.Init.Backcolor.Blue = 0;
  hltdc.Init.Backcolor.Green = 0;
  hltdc.Init.Backcolor.Red = 0;
  if (HAL_LTDC_Init(&hltdc) != HAL_OK)
  {
    Error_Handler();
  }
  pLayerCfg.WindowX0 = 0;
  pLayerCfg.WindowX1 = 480;
  pLayerCfg.WindowY0 = 0;
  pLayerCfg.WindowY1 = 272;
  pLayerCfg.PixelFormat = LTDC_PIXEL_FORMAT_RGB565;
  pLayerCfg.Alpha = 255;
  pLayerCfg.Alpha0 = 0;
  pLayerCfg.BlendingFactor1 = LTDC_BLENDING_FACTOR1_PAxCA;
  pLayerCfg.BlendingFactor2 = LTDC_BLENDING_FACTOR2_PAxCA;
  pLayerCfg.FBStartAdress = 0xC0000000;
  pLayerCfg.ImageWidth = 480;
  pLayerCfg.ImageHeight = 272;
  pLayerCfg.Backcolor.Blue = 0;
  pLayerCfg.Backcolor.Green = 0;
  pLayerCfg.Backcolor.Red = 0;
  if (HAL_LTDC_ConfigLayer(&hltdc, &pLayerCfg, 0) != HAL_OK)
  {
    Error_Handler();
  }
}

static void MX_RNG_Init(void)
{

  hrng.Instance = RNG;
  if (HAL_RNG_Init(&hrng) != HAL_OK)
  {
    Error_Handler();
  }
}

static void MX_TIM1_Init(void)
{

  TIM_ClockConfigTypeDef sClockSourceConfig = {0};
  TIM_MasterConfigTypeDef sMasterConfig = {0};

  htim1.Instance = TIM1;
  htim1.Init.Prescaler = 0;
  htim1.Init.CounterMode = TIM_COUNTERMODE_UP;
  htim1.Init.Period = 65535;
  htim1.Init.ClockDivision = TIM_CLOCKDIVISION_DIV1;
  htim1.Init.RepetitionCounter = 0;
  htim1.Init.AutoReloadPreload = TIM_AUTORELOAD_PRELOAD_DISABLE;
  if (HAL_TIM_Base_Init(&htim1) != HAL_OK)
  {
    Error_Handler();
  }
  sClockSourceConfig.ClockSource = TIM_CLOCKSOURCE_INTERNAL;
  if (HAL_TIM_ConfigClockSource(&htim1, &sClockSourceConfig) != HAL_OK)
  {
    Error_Handler();
  }
  sMasterConfig.MasterOutputTrigger = TIM_TRGO_RESET;
  sMasterConfig.MasterOutputTrigger2 = TIM_TRGO2_RESET;
  sMasterConfig.MasterSlaveMode = TIM_MASTERSLAVEMODE_DISABLE;
  if (HAL_TIMEx_MasterConfigSynchronization(&htim1, &sMasterConfig) != HAL_OK)
  {
    Error_Handler();
  }
}

static void MX_TIM2_Init(void)
{

  TIM_ClockConfigTypeDef sClockSourceConfig = {0};
  TIM_MasterConfigTypeDef sMasterConfig = {0};

  htim2.Instance = TIM2;
  htim2.Init.Prescaler = 0;
  htim2.Init.CounterMode = TIM_COUNTERMODE_UP;
  htim2.Init.Period = 4294967295;
  htim2.Init.ClockDivision = TIM_CLOCKDIVISION_DIV1;
  htim2.Init.AutoReloadPreload = TIM_AUTORELOAD_PRELOAD_DISABLE;
  if (HAL_TIM_Base_Init(&htim2) != HAL_OK)
  {
    Error_Handler();
  }
  sClockSourceConfig.ClockSource = TIM_CLOCKSOURCE_INTERNAL;
  if (HAL_TIM_ConfigClockSource(&htim2, &sClockSourceConfig) != HAL_OK)
  {
    Error_Handler();
  }
  sMasterConfig.MasterOutputTrigger = TIM_TRGO_RESET;
  sMasterConfig.MasterSlaveMode = TIM_MASTERSLAVEMODE_DISABLE;
  if (HAL_TIMEx_MasterConfigSynchronization(&htim2, &sMasterConfig) != HAL_OK)
  {
    Error_Handler();
  }
}

static void MX_TIM3_Init(void)
{

  TIM_ClockConfigTypeDef sClockSourceConfig = {0};
  TIM_SlaveConfigTypeDef sSlaveConfig = {0};
  TIM_MasterConfigTypeDef sMasterConfig = {0};
  TIM_OC_InitTypeDef sConfigOC = {0};

  htim3.Instance = TIM3;
  htim3.Init.Prescaler = 0;
  htim3.Init.CounterMode = TIM_COUNTERMODE_UP;
  htim3.Init.Period = 65535;
  htim3.Init.ClockDivision = TIM_CLOCKDIVISION_DIV1;
  htim3.Init.AutoReloadPreload = TIM_AUTORELOAD_PRELOAD_DISABLE;
  if (HAL_TIM_Base_Init(&htim3) != HAL_OK)
  {
    Error_Handler();
  }
  sClockSourceConfig.ClockSource = TIM_CLOCKSOURCE_INTERNAL;
  if (HAL_TIM_ConfigClockSource(&htim3, &sClockSourceConfig) != HAL_OK)
  {
    Error_Handler();
  }
  if (HAL_TIM_PWM_Init(&htim3) != HAL_OK)
  {
    Error_Handler();
  }
  sSlaveConfig.SlaveMode = TIM_SLAVEMODE_DISABLE;
  sSlaveConfig.InputTrigger = TIM_TS_ITR0;
  if (HAL_TIM_SlaveConfigSynchro(&htim3, &sSlaveConfig) != HAL_OK)
  {
    Error_Handler();
  }
  sMasterConfig.MasterOutputTrigger = TIM_TRGO_RESET;
  sMasterConfig.MasterSlaveMode = TIM_MASTERSLAVEMODE_DISABLE;
  if (HAL_TIMEx_MasterConfigSynchronization(&htim3, &sMasterConfig) != HAL_OK)
  {
    Error_Handler();
  }
  sConfigOC.OCMode = TIM_OCMODE_PWM1;
  sConfigOC.Pulse = 0;
  sConfigOC.OCPolarity = TIM_OCPOLARITY_HIGH;
  sConfigOC.OCFastMode = TIM_OCFAST_DISABLE;
  if (HAL_TIM_PWM_ConfigChannel(&htim3, &sConfigOC, TIM_CHANNEL_1) != HAL_OK)
  {
    Error_Handler();
  }
  HAL_TIM_MspPostInit(&htim3);
}

static void MX_TIM5_Init(void)
{

  TIM_ClockConfigTypeDef sClockSourceConfig = {0};
  TIM_MasterConfigTypeDef sMasterConfig = {0};

  htim5.Instance = TIM5;
  htim5.Init.Prescaler = 0;
  htim5.Init.CounterMode = TIM_COUNTERMODE_UP;
  htim5.Init.Period = 4294967295;
  htim5.Init.ClockDivision = TIM_CLOCKDIVISION_DIV1;
  htim5.Init.AutoReloadPreload = TIM_AUTORELOAD_PRELOAD_DISABLE;
  if (HAL_TIM_Base_Init(&htim5) != HAL_OK)
  {
    Error_Handler();
  }
  sClockSourceConfig.ClockSource = TIM_CLOCKSOURCE_INTERNAL;
  if (HAL_TIM_ConfigClockSource(&htim5, &sClockSourceConfig) != HAL_OK)
  {
    Error_Handler();
  }
  sMasterConfig.MasterOutputTrigger = TIM_TRGO_RESET;
  sMasterConfig.MasterSlaveMode = TIM_MASTERSLAVEMODE_DISABLE;
  if (HAL_TIMEx_MasterConfigSynchronization(&htim5, &sMasterConfig) != HAL_OK)
  {
    Error_Handler();
  }
}

static void MX_TIM8_Init(void)
{

  TIM_ClockConfigTypeDef sClockSourceConfig = {0};
  TIM_MasterConfigTypeDef sMasterConfig = {0};
  TIM_OC_InitTypeDef sConfigOC = {0};
  TIM_BreakDeadTimeConfigTypeDef sBreakDeadTimeConfig = {0};

  htim8.Instance = TIM8;
  htim8.Init.Prescaler = 0;
  htim8.Init.CounterMode = TIM_COUNTERMODE_UP;
  htim8.Init.Period = 65535;
  htim8.Init.ClockDivision = TIM_CLOCKDIVISION_DIV1;
  htim8.Init.RepetitionCounter = 0;
  htim8.Init.AutoReloadPreload = TIM_AUTORELOAD_PRELOAD_DISABLE;
  if (HAL_TIM_Base_Init(&htim8) != HAL_OK)
  {
    Error_Handler();
  }
  sClockSourceConfig.ClockSource = TIM_CLOCKSOURCE_INTERNAL;
  if (HAL_TIM_ConfigClockSource(&htim8, &sClockSourceConfig) != HAL_OK)
  {
    Error_Handler();
  }
  if (HAL_TIM_PWM_Init(&htim8) != HAL_OK)
  {
    Error_Handler();
  }
  sMasterConfig.MasterOutputTrigger = TIM_TRGO_RESET;
  sMasterConfig.MasterOutputTrigger2 = TIM_TRGO2_RESET;
  sMasterConfig.MasterSlaveMode = TIM_MASTERSLAVEMODE_DISABLE;
  if (HAL_TIMEx_MasterConfigSynchronization(&htim8, &sMasterConfig) != HAL_OK)
  {
    Error_Handler();
  }
  sConfigOC.OCMode = TIM_OCMODE_PWM1;
  sConfigOC.Pulse = 0;
  sConfigOC.OCPolarity = TIM_OCPOLARITY_HIGH;
  sConfigOC.OCFastMode = TIM_OCFAST_DISABLE;
  sConfigOC.OCIdleState = TIM_OCIDLESTATE_RESET;
  sConfigOC.OCNIdleState = TIM_OCNIDLESTATE_RESET;
  if (HAL_TIM_PWM_ConfigChannel(&htim8, &sConfigOC, TIM_CHANNEL_4) != HAL_OK)
  {
    Error_Handler();
  }
  sBreakDeadTimeConfig.OffStateRunMode = TIM_OSSR_DISABLE;
  sBreakDeadTimeConfig.OffStateIDLEMode = TIM_OSSI_DISABLE;
  sBreakDeadTimeConfig.LockLevel = TIM_LOCKLEVEL_OFF;
  sBreakDeadTimeConfig.DeadTime = 0;
  sBreakDeadTimeConfig.BreakState = TIM_BREAK_DISABLE;
  sBreakDeadTimeConfig.BreakPolarity = TIM_BREAKPOLARITY_HIGH;
  sBreakDeadTimeConfig.BreakFilter = 0;
  sBreakDeadTimeConfig.Break2State = TIM_BREAK2_DISABLE;
  sBreakDeadTimeConfig.Break2Polarity = TIM_BREAK2POLARITY_HIGH;
  sBreakDeadTimeConfig.Break2Filter = 0;
  sBreakDeadTimeConfig.AutomaticOutput = TIM_AUTOMATICOUTPUT_DISABLE;
  if (HAL_TIMEx_ConfigBreakDeadTime(&htim8, &sBreakDeadTimeConfig) != HAL_OK)
  {
    Error_Handler();
  }
  HAL_TIM_MspPostInit(&htim8);
}

/* FMC initialization function */
static void MX_FMC_Init(void)
{

  FMC_SDRAM_TimingTypeDef SdramTiming = {0};

  /** Perform the SDRAM1 memory initialization sequence
  */
  hsdram1.Instance = FMC_SDRAM_DEVICE;
  /* hsdram1.Init */
  hsdram1.Init.SDBank = FMC_SDRAM_BANK1;
  hsdram1.Init.ColumnBitsNumber = FMC_SDRAM_COLUMN_BITS_NUM_8;
  hsdram1.Init.RowBitsNumber = FMC_SDRAM_ROW_BITS_NUM_12;
  hsdram1.Init.MemoryDataWidth = FMC_SDRAM_MEM_BUS_WIDTH_16;
  hsdram1.Init.InternalBankNumber = FMC_SDRAM_INTERN_BANKS_NUM_4;
  hsdram1.Init.CASLatency = FMC_SDRAM_CAS_LATENCY_1;
  hsdram1.Init.WriteProtection = FMC_SDRAM_WRITE_PROTECTION_DISABLE;
  hsdram1.Init.SDClockPeriod = FMC_SDRAM_CLOCK_DISABLE;
  hsdram1.Init.ReadBurst = FMC_SDRAM_RBURST_DISABLE;
  hsdram1.Init.ReadPipeDelay = FMC_SDRAM_RPIPE_DELAY_0;
  /* SdramTiming */
  SdramTiming.LoadToActiveDelay = 16;
  SdramTiming.ExitSelfRefreshDelay = 16;
  SdramTiming.SelfRefreshTime = 16;
  SdramTiming.RowCycleDelay = 16;
  SdramTiming.WriteRecoveryTime = 16;
  SdramTiming.RPDelay = 16;
  SdramTiming.RCDDelay = 16;

  if (HAL_SDRAM_Init(&hsdram1, &SdramTiming) != HAL_OK)
  {
    Error_Handler();
  }

}

static void MX_GPIO_Init(void)
{
  GPIO_InitTypeDef GPIO_InitStruct = {0};

  /* GPIO Ports Clock Enable */
  __HAL_RCC_GPIOE_CLK_ENABLE();
  __HAL_RCC_GPIOG_CLK_ENABLE();
  __HAL_RCC_GPIOB_CLK_ENABLE();
  __HAL_RCC_GPIOA_CLK_ENABLE();
  __HAL_RCC_GPIOJ_CLK_ENABLE();
  __HAL_RCC_GPIOD_CLK_ENABLE();
  __HAL_RCC_GPIOI_CLK_ENABLE();
  __HAL_RCC_GPIOK_CLK_ENABLE();
  __HAL_RCC_GPIOC_CLK_ENABLE();
  __HAL_RCC_GPIOF_CLK_ENABLE();
  __HAL_RCC_GPIOH_CLK_ENABLE();

  /*Configure GPIO pin Output Level */
  HAL_GPIO_WritePin(GPIOE, LED14_Pin | LED15_Pin, GPIO_PIN_RESET);

  /*Configure GPIO pin Output Level */
  HAL_GPIO_WritePin(OTG_FS_PowerSwitchOn_GPIO_Port, OTG_FS_PowerSwitchOn_Pin, GPIO_PIN_SET);

  /*Configure GPIO pin Output Level */
  HAL_GPIO_WritePin(LED16_GPIO_Port, LED16_Pin, GPIO_PIN_RESET);

  /*Configure GPIO pin Output Level */
  HAL_GPIO_WritePin(LED3_GPIO_Port, LED3_Pin, GPIO_PIN_RESET);

  /*Configure GPIO pin Output Level */
  HAL_GPIO_WritePin(LCD_BL_CTRL_GPIO_Port, LCD_BL_CTRL_Pin, GPIO_PIN_SET);

  /*Configure GPIO pin Output Level */
  HAL_GPIO_WritePin(LCD_DISP_GPIO_Port, LCD_DISP_Pin, GPIO_PIN_SET);

  /*Configure GPIO pin Output Level */
  HAL_GPIO_WritePin(GPIOH, LED13_Pin | LED17_Pin | LED11_Pin | LED12_Pin | LED2_Pin | LED18_Pin, GPIO_PIN_RESET);

  /*Configure GPIO pin Output Level */
  HAL_GPIO_WritePin(EXT_RST_GPIO_Port, EXT_RST_Pin, GPIO_PIN_RESET);

  /*Configure GPIO pin : PE3 */
  GPIO_InitStruct.Pin = GPIO_PIN_3;
  GPIO_InitStruct.Mode = GPIO_MODE_INPUT;
  GPIO_InitStruct.Pull = GPIO_NOPULL;
  HAL_GPIO_Init(GPIOE, &GPIO_InitStruct);

  /*Configure GPIO pins : ARDUINO_SCL_D15_Pin ARDUINO_SDA_D14_Pin */
  GPIO_InitStruct.Pin = ARDUINO_SCL_D15_Pin | ARDUINO_SDA_D14_Pin;
  GPIO_InitStruct.Mode = GPIO_MODE_AF_OD;
  GPIO_InitStruct.Pull = GPIO_PULLUP;
  GPIO_InitStruct.Speed = GPIO_SPEED_FREQ_LOW;
  GPIO_InitStruct.Alternate = GPIO_AF4_I2C1;
  HAL_GPIO_Init(GPIOB, &GPIO_InitStruct);

  /*Configure GPIO pins : ULPI_D7_Pin ULPI_D6_Pin ULPI_D5_Pin ULPI_D2_Pin
                           ULPI_D1_Pin ULPI_D4_Pin */
  GPIO_InitStruct.Pin = ULPI_D7_Pin | ULPI_D6_Pin | ULPI_D5_Pin | ULPI_D2_Pin | ULPI_D1_Pin | ULPI_D4_Pin;
  GPIO_InitStruct.Mode = GPIO_MODE_AF_PP;
  GPIO_InitStruct.Pull = GPIO_NOPULL;
  GPIO_InitStruct.Speed = GPIO_SPEED_FREQ_VERY_HIGH;
  GPIO_InitStruct.Alternate = GPIO_AF10_OTG_HS;
  HAL_GPIO_Init(GPIOB, &GPIO_InitStruct);

  /*Configure GPIO pins : BP2_Pin BP1_Pin */
  GPIO_InitStruct.Pin = BP2_Pin | BP1_Pin;
  GPIO_InitStruct.Mode = GPIO_MODE_INPUT;
  GPIO_InitStruct.Pull = GPIO_NOPULL;
  HAL_GPIO_Init(GPIOA, &GPIO_InitStruct);

  /*Configure GPIO pins : LED14_Pin LED15_Pin */
  GPIO_InitStruct.Pin = LED14_Pin | LED15_Pin;
  GPIO_InitStruct.Mode = GPIO_MODE_OUTPUT_PP;
  GPIO_InitStruct.Pull = GPIO_NOPULL;
  GPIO_InitStruct.Speed = GPIO_SPEED_FREQ_LOW;
  HAL_GPIO_Init(GPIOE, &GPIO_InitStruct);

  /*Configure GPIO pin : VCP_RX_Pin */
  GPIO_InitStruct.Pin = VCP_RX_Pin;
  GPIO_InitStruct.Mode = GPIO_MODE_AF_PP;
  GPIO_InitStruct.Pull = GPIO_NOPULL;
  GPIO_InitStruct.Speed = GPIO_SPEED_FREQ_LOW;
  GPIO_InitStruct.Alternate = GPIO_AF7_USART1;
  HAL_GPIO_Init(VCP_RX_GPIO_Port, &GPIO_InitStruct);

  /*Configure GPIO pin : OTG_FS_VBUS_Pin */
  GPIO_InitStruct.Pin = OTG_FS_VBUS_Pin;
  GPIO_InitStruct.Mode = GPIO_MODE_INPUT;
  GPIO_InitStruct.Pull = GPIO_NOPULL;
  HAL_GPIO_Init(OTG_FS_VBUS_GPIO_Port, &GPIO_InitStruct);

  /*Configure GPIO pin : Audio_INT_Pin */
  GPIO_InitStruct.Pin = Audio_INT_Pin;
  GPIO_InitStruct.Mode = GPIO_MODE_EVT_RISING;
  GPIO_InitStruct.Pull = GPIO_NOPULL;
  HAL_GPIO_Init(Audio_INT_GPIO_Port, &GPIO_InitStruct);

  /*Configure GPIO pins : OTG_FS_PowerSwitchOn_Pin LED16_Pin */
  GPIO_InitStruct.Pin = OTG_FS_PowerSwitchOn_Pin | LED16_Pin;
  GPIO_InitStruct.Mode = GPIO_MODE_OUTPUT_PP;
  GPIO_InitStruct.Pull = GPIO_NOPULL;
  GPIO_InitStruct.Speed = GPIO_SPEED_FREQ_LOW;
  HAL_GPIO_Init(GPIOD, &GPIO_InitStruct);

  /*Configure GPIO pins : LED3_Pin LCD_DISP_Pin */
  GPIO_InitStruct.Pin = LED3_Pin | LCD_DISP_Pin;
  GPIO_InitStruct.Mode = GPIO_MODE_OUTPUT_PP;
  GPIO_InitStruct.Pull = GPIO_NOPULL;
  GPIO_InitStruct.Speed = GPIO_SPEED_FREQ_LOW;
  HAL_GPIO_Init(GPIOI, &GPIO_InitStruct);

  /*Configure GPIO pin : uSD_Detect_Pin */
  GPIO_InitStruct.Pin = uSD_Detect_Pin;
  GPIO_InitStruct.Mode = GPIO_MODE_INPUT;
  GPIO_InitStruct.Pull = GPIO_NOPULL;
  HAL_GPIO_Init(uSD_Detect_GPIO_Port, &GPIO_InitStruct);

  /*Configure GPIO pin : LCD_BL_CTRL_Pin */
  GPIO_InitStruct.Pin = LCD_BL_CTRL_Pin;
  GPIO_InitStruct.Mode = GPIO_MODE_OUTPUT_PP;
  GPIO_InitStruct.Pull = GPIO_NOPULL;
  GPIO_InitStruct.Speed = GPIO_SPEED_FREQ_LOW;
  HAL_GPIO_Init(LCD_BL_CTRL_GPIO_Port, &GPIO_InitStruct);

  /*Configure GPIO pin : OTG_FS_OverCurrent_Pin */
  GPIO_InitStruct.Pin = OTG_FS_OverCurrent_Pin;
  GPIO_InitStruct.Mode = GPIO_MODE_INPUT;
  GPIO_InitStruct.Pull = GPIO_NOPULL;
  HAL_GPIO_Init(OTG_FS_OverCurrent_GPIO_Port, &GPIO_InitStruct);

  /*Configure GPIO pins : TP3_Pin NC2_Pin */
  GPIO_InitStruct.Pin = TP3_Pin | NC2_Pin;
  GPIO_InitStruct.Mode = GPIO_MODE_INPUT;
  GPIO_InitStruct.Pull = GPIO_NOPULL;
  HAL_GPIO_Init(GPIOH, &GPIO_InitStruct);

  /*Configure GPIO pin : ARDUINO_SCK_D13_Pin */
  GPIO_InitStruct.Pin = ARDUINO_SCK_D13_Pin;
  GPIO_InitStruct.Mode = GPIO_MODE_AF_PP;
  GPIO_InitStruct.Pull = GPIO_NOPULL;
  GPIO_InitStruct.Speed = GPIO_SPEED_FREQ_LOW;
  GPIO_InitStruct.Alternate = GPIO_AF5_SPI2;
  HAL_GPIO_Init(ARDUINO_SCK_D13_GPIO_Port, &GPIO_InitStruct);

  /*Configure GPIO pins : LED13_Pin LED17_Pin LED11_Pin LED12_Pin
                           LED2_Pin LED18_Pin */
  GPIO_InitStruct.Pin = LED13_Pin | LED17_Pin | LED11_Pin | LED12_Pin | LED2_Pin | LED18_Pin;
  GPIO_InitStruct.Mode = GPIO_MODE_OUTPUT_PP;
  GPIO_InitStruct.Pull = GPIO_NOPULL;
  GPIO_InitStruct.Speed = GPIO_SPEED_FREQ_LOW;
  HAL_GPIO_Init(GPIOH, &GPIO_InitStruct);

  /*Configure GPIO pin : PI0 */
  GPIO_InitStruct.Pin = GPIO_PIN_0;
  GPIO_InitStruct.Mode = GPIO_MODE_AF_PP;
  GPIO_InitStruct.Pull = GPIO_NOPULL;
  GPIO_InitStruct.Speed = GPIO_SPEED_FREQ_VERY_HIGH;
  GPIO_InitStruct.Alternate = GPIO_AF5_SPI2;
  HAL_GPIO_Init(GPIOI, &GPIO_InitStruct);

  /*Configure GPIO pin : VCP_TX_Pin */
  GPIO_InitStruct.Pin = VCP_TX_Pin;
  GPIO_InitStruct.Mode = GPIO_MODE_AF_PP;
  GPIO_InitStruct.Pull = GPIO_NOPULL;
  GPIO_InitStruct.Speed = GPIO_SPEED_FREQ_LOW;
  GPIO_InitStruct.Alternate = GPIO_AF7_USART1;
  HAL_GPIO_Init(VCP_TX_GPIO_Port, &GPIO_InitStruct);

  /*Configure GPIO pin : LCD_INT_Pin */
  GPIO_InitStruct.Pin = LCD_INT_Pin;
  GPIO_InitStruct.Mode = GPIO_MODE_EVT_RISING;
  GPIO_InitStruct.Pull = GPIO_NOPULL;
  HAL_GPIO_Init(LCD_INT_GPIO_Port, &GPIO_InitStruct);

  /*Configure GPIO pins : PC7 PC6 */
  GPIO_InitStruct.Pin = GPIO_PIN_7 | GPIO_PIN_6;
  GPIO_InitStruct.Mode = GPIO_MODE_AF_PP;
  GPIO_InitStruct.Pull = GPIO_NOPULL;
  GPIO_InitStruct.Speed = GPIO_SPEED_FREQ_VERY_HIGH;
  GPIO_InitStruct.Alternate = GPIO_AF8_USART6;
  HAL_GPIO_Init(GPIOC, &GPIO_InitStruct);

  /*Configure GPIO pin : ULPI_NXT_Pin */
  GPIO_InitStruct.Pin = ULPI_NXT_Pin;
  GPIO_InitStruct.Mode = GPIO_MODE_AF_PP;
  GPIO_InitStruct.Pull = GPIO_NOPULL;
  GPIO_InitStruct.Speed = GPIO_SPEED_FREQ_VERY_HIGH;
  GPIO_InitStruct.Alternate = GPIO_AF10_OTG_HS;
  HAL_GPIO_Init(ULPI_NXT_GPIO_Port, &GPIO_InitStruct);

  /*Configure GPIO pins : BP_JOYSTICK_Pin RMII_RXER_Pin */
  GPIO_InitStruct.Pin = BP_JOYSTICK_Pin | RMII_RXER_Pin;
  GPIO_InitStruct.Mode = GPIO_MODE_INPUT;
  GPIO_InitStruct.Pull = GPIO_NOPULL;
  HAL_GPIO_Init(GPIOG, &GPIO_InitStruct);

  /*Configure GPIO pin : PF7 */
  GPIO_InitStruct.Pin = GPIO_PIN_7;
  GPIO_InitStruct.Mode = GPIO_MODE_AF_PP;
  GPIO_InitStruct.Pull = GPIO_NOPULL;
  GPIO_InitStruct.Speed = GPIO_SPEED_FREQ_VERY_HIGH;
  GPIO_InitStruct.Alternate = GPIO_AF8_UART7;
  HAL_GPIO_Init(GPIOF, &GPIO_InitStruct);

  /*Configure GPIO pins : ULPI_STP_Pin ULPI_DIR_Pin */
  GPIO_InitStruct.Pin = ULPI_STP_Pin | ULPI_DIR_Pin;
  GPIO_InitStruct.Mode = GPIO_MODE_AF_PP;
  GPIO_InitStruct.Pull = GPIO_NOPULL;
  GPIO_InitStruct.Speed = GPIO_SPEED_FREQ_VERY_HIGH;
  GPIO_InitStruct.Alternate = GPIO_AF10_OTG_HS;
  HAL_GPIO_Init(GPIOC, &GPIO_InitStruct);

  /*Configure GPIO pin : EXT_RST_Pin */
  GPIO_InitStruct.Pin = EXT_RST_Pin;
  GPIO_InitStruct.Mode = GPIO_MODE_OUTPUT_PP;
  GPIO_InitStruct.Pull = GPIO_NOPULL;
  GPIO_InitStruct.Speed = GPIO_SPEED_FREQ_LOW;
  HAL_GPIO_Init(EXT_RST_GPIO_Port, &GPIO_InitStruct);

  /*Configure GPIO pins : LCD_SCL_Pin LCD_SDA_Pin */
  GPIO_InitStruct.Pin = LCD_SCL_Pin | LCD_SDA_Pin;
  GPIO_InitStruct.Mode = GPIO_MODE_AF_OD;
  GPIO_InitStruct.Pull = GPIO_PULLUP;
  GPIO_InitStruct.Speed = GPIO_SPEED_FREQ_VERY_HIGH;
  GPIO_InitStruct.Alternate = GPIO_AF4_I2C3;
  HAL_GPIO_Init(GPIOH, &GPIO_InitStruct);

  /*Configure GPIO pins : ULPI_CLK_Pin ULPI_D0_Pin */
  GPIO_InitStruct.Pin = ULPI_CLK_Pin | ULPI_D0_Pin;
  GPIO_InitStruct.Mode = GPIO_MODE_AF_PP;
  GPIO_InitStruct.Pull = GPIO_NOPULL;
  GPIO_InitStruct.Speed = GPIO_SPEED_FREQ_VERY_HIGH;
  GPIO_InitStruct.Alternate = GPIO_AF10_OTG_HS;
  HAL_GPIO_Init(GPIOA, &GPIO_InitStruct);

  /*Configure GPIO pins : PB14 PB15 */
  GPIO_InitStruct.Pin = GPIO_PIN_14 | GPIO_PIN_15;
  GPIO_InitStruct.Mode = GPIO_MODE_AF_PP;
  GPIO_InitStruct.Pull = GPIO_NOPULL;
  GPIO_InitStruct.Speed = GPIO_SPEED_FREQ_VERY_HIGH;
  GPIO_InitStruct.Alternate = GPIO_AF5_SPI2;
  HAL_GPIO_Init(GPIOB, &GPIO_InitStruct);
}

/* USER CODE BEGIN 4 */

const uint32_t Couleur_joueur = LCD_COLOR_CYAN;
const uint32_t Couleur_monstre = LCD_COLOR_RED;
const uint32_t Couleur_missile = LCD_COLOR_WHITE;
const uint32_t Couleur_vide = LCD_COLOR_BLACK;
//const ip_addr_t IP_REGULUS = (45 << (3 * 8)) + (66 << (2 * 8)) + (110 << (1 * 8)) + (180 << (0 * 8));
/*
static int envoie_score(int score)
{
  struct udp_pcb socket;
  &socket = new_udp();

  return 0;
}
 */
void repopulate_ennemie_list(uint8_t wave)
{
  int idx1;
  int idx2;
  for (idx1 = 0; idx1 < 8; idx1++)
  {
    for (idx2 = 0; idx2 < 3; idx2++)
    {
      Table_ennemis[idx1][idx2].x = (2 * idx1 + 2) * monstre_width;
      Table_ennemis[idx1][idx2].y = (2 * idx2 + 1) * monstre_height;
      Table_ennemis[idx1][idx2].health = 1; // wave / 2 + 1;
      Table_ennemis[idx1][idx2].missile.x = 0;
      Table_ennemis[idx1][idx2].missile.y = 0;
      Table_ennemis[idx1][idx2].missile.dx = 1;
      Table_ennemis[idx1][idx2].missile.dy = 0;
      Table_ennemis[idx1][idx2].missile.equipe = 0;
      Table_ennemis[idx1][idx2].missile.damage = 1; // wave / 2 + 1;
      Table_ennemis[idx1][idx2].missile.valide = 1;
      if (proba_bernoulli(1, 3))
        Table_ennemis[idx1][idx2].health = 0;
    }
  }
}

/*
  * @brief  Encapsulation du tracer d'un rectangle
  * @param  pos_x
  * @retval None
  */
void lcd_plot_rect(uint16_t pos_x, uint16_t pos_y, uint16_t taille_x, uint16_t taille_y, uint32_t color)
{
  while (xSemaphoreTake(MutexLCDHandle, (TickType_t)10) != pdPASS)
    ;
  BSP_LCD_SetTextColor(color);
  BSP_LCD_FillRect(pos_x, pos_y, taille_x, taille_y);
  xSemaphoreGive(MutexLCDHandle);
}

void lcd_plot_circ(uint16_t pos_x, uint16_t pos_y, uint16_t rad, uint32_t color)
{
  while (xSemaphoreTake(MutexLCDHandle, (TickType_t)10) != pdPASS)
    ;
  BSP_LCD_SetTextColor(color);
  if (rad == 0)
    rad = 1;
  BSP_LCD_FillCircle(pos_x, pos_y, rad);
  xSemaphoreGive(MutexLCDHandle);
}

void lcd_plot_text_pos(uint16_t pos_x, uint16_t pos_y, uint8_t *text, uint32_t color, Text_AlignModeTypdef mode)
{
  while (xSemaphoreTake(MutexLCDHandle, (TickType_t)10) != pdPASS)
    ;
  BSP_LCD_SetTextColor(color);
  BSP_LCD_SetBackColor(Couleur_vide);
  BSP_LCD_DisplayStringAt(pos_x, pos_y, text, mode);
  xSemaphoreGive(MutexLCDHandle);
}

void lcd_plot_text_line(uint16_t line, uint8_t *text, uint32_t color)
{
  while (xSemaphoreTake(MutexLCDHandle, (TickType_t)10) != pdPASS)
    ;
  BSP_LCD_SetTextColor(color);
  BSP_LCD_SetBackColor(Couleur_vide);
  BSP_LCD_DisplayStringAtLine(line, text);
  xSemaphoreGive(MutexLCDHandle);
}

uint8_t proba_bernoulli(uint32_t numerateur, uint32_t denominateur)
{
  uint32_t nombre_aleatoire;
  while (HAL_RNG_GenerateRandomNumber(&hrng, &nombre_aleatoire) != HAL_OK)
    ;
  uint32_t limite;
  limite = UINT32_MAX;
  limite /= denominateur;
  limite *= numerateur;
  if (nombre_aleatoire > limite)
    return 0;
  else
    return 1;
}

uint8_t colision_missile(uint16_t m_pos_x, uint16_t m_pos_y, uint16_t o_pos_x, uint16_t o_pos_y, uint16_t o_taille_x, uint16_t o_taille_y)
{
  return ((m_pos_x > o_pos_x) & (m_pos_x < o_pos_x + o_taille_x) & (m_pos_y > o_pos_y) & (m_pos_y < o_pos_y + o_taille_y));
}
/* USER CODE END 4 */

void f_GameMaster(void const *argument)
{
  /* init code for LWIP */
  MX_LWIP_Init();
  /* USER CODE BEGIN 5 */
  TickType_t xLastWakeTime;
  xLastWakeTime = xTaskGetTickCount();
  const TickType_t xPeriodeTache = 100 / portTICK_PERIOD_MS;
  repopulate_ennemie_list(wave);
  enum End_type end;
  /* Infinite loop */
  for (;;)
  {
    while (xQueueReceive(Queue_FHandle, &end, (TickType_t)10) != pdPASS)
      ; // Tant qu'il n'y a pas de nouveau message

    if (end == END_MORT_JOUEUR)
    {
      vTaskDelete(Block_EnemieHandle);
      vTaskDelete(ProjectileHandle);
      vTaskDelete(Joueur_1Handle);
      uint8_t msg[] = "GAME OVER";
      lcd_plot_text_pos(BSP_LCD_GetXSize() / 2, BSP_LCD_GetYSize() / 2, msg, Couleur_joueur, CENTER_MODE);
      //TODO L'affichage de l'écran de fin et des scores
    }

    if (end == END_TABLEAU_VIDE)
    {
      wave++;
      repopulate_ennemie_list(wave);
    }
    vTaskDelayUntil(&xLastWakeTime, xPeriodeTache);
  }
  /* USER CODE END 5 */
}

void f_Joueur_1(void const *argument)
{
  /* USER CODE BEGIN f_Joueur_1 */
  TickType_t xLastWakeTime;
  xLastWakeTime = xTaskGetTickCount();

  const TickType_t xPeriodeTache = 5 / portTICK_PERIOD_MS;
  uint32_t joystick_h, joystick_v;

  struct Missile missile;

  uint8_t bouton_relache = 1;

  ADC_ChannelConfTypeDef sConfig3 = {0};
  sConfig3.Rank = ADC_REGULAR_RANK_1;
  sConfig3.SamplingTime = ADC_SAMPLETIME_3CYCLES;
  sConfig3.Channel = ADC_CHANNEL_8;

  HAL_ADC_ConfigChannel(&hadc3, &sConfig3);
  HAL_ADC_Start(&hadc3);

  ADC_ChannelConfTypeDef sConfig1 = {0};
  sConfig1.Rank = ADC_REGULAR_RANK_1;
  sConfig1.SamplingTime = ADC_SAMPLETIME_3CYCLES;
  sConfig1.Channel = ADC_CHANNEL_0;

  HAL_ADC_ConfigChannel(&hadc1, &sConfig1);
  HAL_ADC_Start(&hadc1);

  enum End_type end = END_MORT_JOUEUR;
  // Paramètre de l'écran pour la reprouductibilité

  uint32_t LCD_HEIGHT = BSP_LCD_GetXSize();
  uint32_t LCD_WIDTH = BSP_LCD_GetYSize();

  const uint32_t seuil_joystick = 200;
  const uint32_t centre_joystick = 2048;
  /* Infinite loop */
  for (;;)
  {
    lcd_plot_rect(joueur.x, joueur.y, joueur_width, joueur_height, Couleur_vide);
    // BSP_LCD_DrawBitmap(uint32_t Xpos, uint32_t Ypos, uint8_t *pbmp)
    HAL_ADC_ConfigChannel(&hadc3, &sConfig3);
    HAL_ADC_Start(&hadc3);
    while (HAL_ADC_PollForConversion(&hadc3, 100) != HAL_OK)
      ;
    joystick_h = HAL_ADC_GetValue(&hadc3);

    HAL_ADC_ConfigChannel(&hadc1, &sConfig1);
    HAL_ADC_Start(&hadc1);
    while (HAL_ADC_PollForConversion(&hadc1, 100) != HAL_OK)
      ;
    joystick_v = HAL_ADC_GetValue(&hadc1);

    if ((joueur.y < LCD_WIDTH - joueur_width - joueur.dy) && (joystick_h < centre_joystick - seuil_joystick))
      joueur.y += joueur.dy;
    if ((joueur.y > joueur.dy) && (joystick_h > centre_joystick + seuil_joystick))
      joueur.y -= joueur.dy;

    if ((joueur.x < LCD_HEIGHT - joueur_height - joueur.dx) && (joystick_v < centre_joystick - seuil_joystick))
      joueur.x += joueur.dx;
    if ((joueur.x > joueur.dx) && (joystick_v > centre_joystick + seuil_joystick))
      joueur.x -= joueur.dx;

    lcd_plot_rect(joueur.x, joueur.y, joueur_width, joueur_height, Couleur_joueur);

    if (xQueueReceive(Queue_JHandle, &missile, 0) == pdPASS)
      joueur.health = joueur.health - missile.damage;
    // On envoie 1 si le joueur est mort et on envoie 0 si les enemis sont tous morts
    if (joueur.health <= 0)
      xQueueSend(Queue_FHandle, &end, 0);

    if ((!HAL_GPIO_ReadPin(BP1_GPIO_Port, BP1_Pin)) && bouton_relache)
    {
      bouton_relache = 0;
      missile = joueur.missile;
      missile.x = joueur.x + joueur_width / 2;
      missile.y = joueur.y;
      xQueueSend(Queue_NHandle, &missile, 0);
      HAL_GPIO_TogglePin(LED11_GPIO_Port, LED11_Pin);
    }
    if (HAL_GPIO_ReadPin(BP1_GPIO_Port, BP1_Pin))

      bouton_relache = 1;

    vTaskDelayUntil(&xLastWakeTime, xPeriodeTache);
  }
  /* USER CODE END f_Joueur_1 */
}

void f_block_enemie(void const *argument)
{
  /* USER CODE BEGIN f_block_enemie */

  TickType_t xLastWakeTime;
  xLastWakeTime = xTaskGetTickCount();
  const TickType_t xPeriodeTache = 200 / portTICK_PERIOD_MS; // Toute les demi secondes
  uint8_t nombre_monstre;
  struct Collision collision;

  int8_t vitesse = 5;
  enum Sens_ennemie direction = DROITE;

  struct Missile missile = {0, 0, 0, 1, MISSILE_ENNEMI, 1, 1};
  int32_t lim_droite;
  int32_t lim_gauche;
  /* Infinite loop */
  for (;;)
  {
    while (xQueueReceive(Queue_EHandle, &collision, 0) == pdPASS)
    {
      Table_ennemis[collision.idx1][collision.idx2].health -= collision.damage;
    }

    for (int idx1 = 0; idx1 < 8; idx1++)
    {
      for (int idx2 = 0; idx2 < 3; idx2++)
      {
        lcd_plot_rect(Table_ennemis[idx1][idx2].x, Table_ennemis[idx1][idx2].y, monstre_width, monstre_height, Couleur_vide);
      }
    }
    lim_droite = Table_ennemis[0][0].x;
    lim_gauche = Table_ennemis[0][0].x;
    for (int idx1 = 0; idx1 < 8; idx1++)
    {
      for (int idx2 = 0; idx2 < 3; idx2++)
      {
        if ((Table_ennemis[idx1][idx2].x > lim_droite) && (Table_ennemis[idx1][idx2].health > 0))
          lim_droite = Table_ennemis[idx1][idx2].x;
        if ((Table_ennemis[idx1][idx2].x < lim_gauche) && (Table_ennemis[idx1][idx2].health > 0))
          lim_gauche = Table_ennemis[idx1][idx2].x;
      }
    }

    if ((direction == DROITE) && (lim_droite + vitesse + monstre_width >= BSP_LCD_GetXSize()))
      direction = GAUCHE;

    else if ((direction == GAUCHE) && (lim_gauche <= vitesse))
      direction = DROITE;

    for (int idx1 = 0; idx1 < 8; idx1++)
    {
      for (int idx2 = 0; idx2 < 3; idx2++)
      {
        if (direction == DROITE)
          Table_ennemis[idx1][idx2].x += vitesse;
        if (direction == GAUCHE)
          Table_ennemis[idx1][idx2].x -= vitesse;
      }
    }
    // TODO déplacement des ennemies

    nombre_monstre = 0;
    for (int idx1 = 0; idx1 < 8; idx1++)
    {
      for (int idx2 = 0; idx2 < 3; idx2++)
      {
        if (Table_ennemis[idx1][idx2].health > 0)
        {
          nombre_monstre++;
          lcd_plot_rect(Table_ennemis[idx1][idx2].x, Table_ennemis[idx1][idx2].y, monstre_width, monstre_height, Couleur_monstre);
        }
      }
    }
    if (!nombre_monstre)
    {
      enum End_type end = END_TABLEAU_VIDE;
      xQueueSend(Queue_FHandle, &end, 0);
    }

    for (int idx1 = 0; idx1 < 8; idx1++)
    {
      for (int idx2 = 0; idx2 < 3; idx2++)
      {
        if (Table_ennemis[idx1][idx2].health > 0)
        {
          if (proba_bernoulli(wave, 32))
          {
            missile.x = Table_ennemis[idx1][idx2].x + monstre_width / 2;
            missile.y = Table_ennemis[idx1][idx2].y + monstre_height;
            xQueueSend(Queue_NHandle, &missile, 0);
          }
        }
      }
    }
    vTaskDelayUntil(&xLastWakeTime, xPeriodeTache);
  }
  /* USER CODE END f_block_enemie */
}

void f_projectile(void const *argument)
{
  /* USER CODE BEGIN f_projectile */
  TickType_t xLastWakeTime;
  xLastWakeTime = xTaskGetTickCount();
  const TickType_t xPeriodeTache = 10 / portTICK_PERIOD_MS; // Toutes les 200 ms
  const int TAILLE_LISTE_MISSILE = 100;
  /* Infinite loop */
  struct Missile liste_missile[TAILLE_LISTE_MISSILE];
  struct Missile missile = {70, 70, 0, 3, MISSILE_ENNEMI, 1, 0};
  liste_missile[0] = missile;
  uint32_t new_x;
  uint32_t new_y;
  // Paramètre de l'écran pour la reprouductibilité

  uint32_t LCD_HEIGHT = BSP_LCD_GetYSize();
  uint32_t LCD_WIDTH = BSP_LCD_GetXSize();

  for (int idx_missile = 0; idx_missile < TAILLE_LISTE_MISSILE; idx_missile++)
    liste_missile[idx_missile] = missile;
  for (;;)
  {
    while (xQueueReceive(Queue_NHandle, &missile, 0) == pdPASS)
    {
      for (int idx_missile = 0; idx_missile < TAILLE_LISTE_MISSILE; idx_missile++)
      {
        if (liste_missile[idx_missile].valide == 0)
        {
          liste_missile[idx_missile] = missile;
          break;
        }
      }
    }

    for (int idx_missile = 0; idx_missile < TAILLE_LISTE_MISSILE; idx_missile++)
    {
      if (liste_missile[idx_missile].valide)
      {
        lcd_plot_circ(liste_missile[idx_missile].x, liste_missile[idx_missile].y, liste_missile[idx_missile].damage, Couleur_vide);

        new_x = liste_missile[idx_missile].x + liste_missile[idx_missile].dx;
        new_y = liste_missile[idx_missile].y + liste_missile[idx_missile].dy;
        if ((new_x <= 0) | (new_x >= LCD_WIDTH) | (new_y <= 0) | (new_y >= LCD_HEIGHT)) //Missile hors de l'écran
          liste_missile[idx_missile].valide = 0;
        if ((liste_missile[idx_missile].equipe == MISSILE_ENNEMI) & colision_missile(new_x, new_y, joueur.x, joueur.y, joueur_width, joueur_height))
        { //TODO condition de choc avec le joueur
          xQueueSend(Queue_JHandle, &liste_missile[idx_missile], 0);
          liste_missile[idx_missile].valide = 0;
        }
        if (liste_missile[idx_missile].equipe == MISSILE_AMI)
        {
          for (int idx_mechant_1 = 0; idx_mechant_1 < 8; idx_mechant_1++)
          {
            for (int idx_mechant_2 = 0; idx_mechant_2 < 3; idx_mechant_2++)
            {
              if ((colision_missile(new_x, new_y, Table_ennemis[idx_mechant_1][idx_mechant_2].x, Table_ennemis[idx_mechant_1][idx_mechant_2].y, monstre_width, monstre_height)) && (Table_ennemis[idx_mechant_1][idx_mechant_2].health > 0))
              {
                struct Collision collision = {idx_mechant_1, idx_mechant_2, liste_missile[idx_missile].damage};
                xQueueSend(Queue_EHandle, (void *)&collision, 0);
                liste_missile[idx_missile].valide = 0;
              }
            }
          }
        }

        liste_missile[idx_missile].x = new_x;
        liste_missile[idx_missile].y = new_y;

        if (liste_missile[idx_missile].valide)
          lcd_plot_circ(liste_missile[idx_missile].x, liste_missile[idx_missile].y, liste_missile[idx_missile].damage, Couleur_missile);
        //TODO effacage
        //TODO nouvelle position
      }
    }
    vTaskDelayUntil(&xLastWakeTime, xPeriodeTache);
  }

  /* USER CODE END f_projectile */
}

void f_HUD(void const *argument)
{
  /* USER CODE BEGIN f_HUD */
  TickType_t xLastWakeTime;
  xLastWakeTime = xTaskGetTickCount();
  const TickType_t xPeriodeTache = 100 / portTICK_PERIOD_MS; // Toutes les 200 ms
  uint8_t line_hud[50] = "";
  const uint8_t base[50] = "vie : %2u  -  vague : %2u";
  /* Infinite loop */
  for (;;)
  {
    sprintf(line_hud, base, (uint)joueur.health, (uint)wave);
    lcd_plot_text_line(0, line_hud, Couleur_missile);
    vTaskDelayUntil(&xLastWakeTime, xPeriodeTache);
  }
  /* USER CODE END f_HUD */
}

void HAL_TIM_PeriodElapsedCallback(TIM_HandleTypeDef *htim)
{
  if (htim->Instance == TIM6)
  {
    HAL_IncTick();
  }
}

void Error_Handler(void)
{
  __disable_irq();
  while (1)
  {
  }
}

/************************ (C) COPYRIGHT STMicroelectronics *****END OF FILE****/
